# ATmega16A device description
Architecture: AVR8; Family: megaAVR
Registers are 8-bit, access not given, no defined reset value unless marked. A register's access mark holds for its fields unless they carry their own. Offsets are from the block's base; [hi:lo] are bit positions.

## TWI — Two Wire Serial Interface
Instances: TWI 0x00
0x20 TWBR — TWI Bit Rate register
  [7:0] TWBR — TWI Bit Rate bits
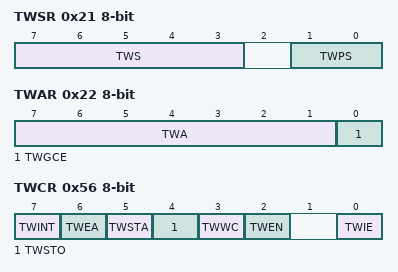
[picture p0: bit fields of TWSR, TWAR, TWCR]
0x21 TWSR — TWI Status Register
  [7:3] TWS (bit 3 of the value upward) — TWI Status
  [1:0] TWPS — TWI Prescaler
    0=1; 1=4; 2=16; 3=64
0x22 TWAR — TWI (Slave) Address register
  [7:1] TWA — TWI (Slave) Address register Bits
  [0] TWGCE — TWI General Call Recognition Enable Bit
0x23 TWDR — TWI Data register
  [7:0] TWD — TWI Data bits
0x56 TWCR — TWI Control Register
  [7] TWINT — TWI Interrupt Flag
  [6] TWEA — TWI Enable Acknowledge Bit
  [5] TWSTA — TWI Start Condition Bit
  [4] TWSTO — TWI Stop Condition Bit
  [3] TWWC — TWI Write Collition Flag
  [2] TWEN — TWI Enable Bit
  [0] TWIE — TWI Interrupt Enable

## AC — Analog Comparator
Instances: AC 0x00
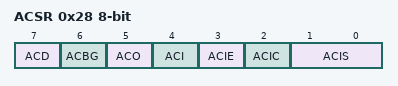
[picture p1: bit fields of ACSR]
0x28 ACSR — Analog Comparator Control And Status Register
  [7] ACD — Analog Comparator Disable
  [6] ACBG — Analog Comparator Bandgap Select
  [5] ACO — Analog Compare Output
  [4] ACI — Analog Comparator Interrupt Flag
  [3] ACIE — Analog Comparator Interrupt Enable
  [2] ACIC — Analog Comparator Input Capture Enable
  [1:0] ACIS — Analog Comparator Interrupt Mode Select bits
    0=Interrupt on Toggle; 2=Interrupt on Falling Edge; 3=Interrupt on Rising Edge
0x50 SFIOR — Special Function IO Register
  [3] ACME — Analog Comparator Multiplexer Enable

## ADC — Analog-to-Digital Converter
Instances: ADC 0x00
0x24 ADC 16-bit — ADC Data Register Bytes
  [9:0] ADC — ADC Data Bits
    0=2; 1=2; 2=4; 3=8; 4=16; 5=32; 6=64; 7=128
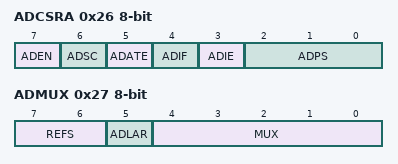
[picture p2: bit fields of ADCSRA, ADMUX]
0x26 ADCSRA — The ADC Control and Status register
  [7] ADEN — ADC Enable
  [6] ADSC — ADC Start Conversion
  [5] ADATE — ADC Auto Trigger
  [4] ADIF — ADC Interrupt Flag
  [3] ADIE — ADC Interrupt Enable
  [2:0] ADPS — ADC Prescaler Select Bits
    0=2; 1=2; 2=4; 3=8; 4=16; 5=32; 6=64; 7=128
0x27 ADMUX — The ADC multiplexer Selection Register
  [7:6] REFS — Reference Selection Bits
    0=AREF, Internal Vref turned off; 1=AVCC with external capacitor at AREF pin; 3=Internal 2.56V Voltage Reference with external capacitor at AREF pin
  [5] ADLAR — Left Adjust Result
  [4:0] MUX — Analog Channel and Gain Selection Bits
0x50 SFIOR — Special Function IO Register
  [7:5] ADTS — ADC Auto Trigger Sources

## JTAG — JTAG Interface
Instances: JTAG 0x00
0x51 OCDR — On-Chip Debug Related Register in I/O Memory
  [7:0] OCDR — On-Chip Debug Register Bits
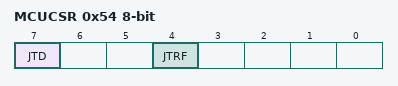
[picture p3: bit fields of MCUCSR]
0x54 MCUCSR — MCU Control And Status Register
  [7] JTD — JTAG Interface Disable
  [4] JTRF — JTAG Reset Flag

## BOOT_LOAD — Bootloader
Instances: BOOT_LOAD 0x00
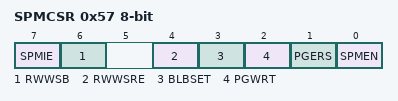
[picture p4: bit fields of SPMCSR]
0x57 SPMCSR — Store Program Memory Control Register
  [7] SPMIE — SPM Interrupt Enable
  [6] RWWSB — Read While Write Section Busy
  [4] RWWSRE — Read While Write section read enable
  [3] BLBSET — Boot Lock Bit Set
  [2] PGWRT — Page Write
  [1] PGERS — Page Erase
  [0] SPMEN — Store Program Memory Enable

## PORTA — I/O Port
Instances: PORTA 0x00
0x39 PINA — Port A Input Pins
0x3A DDRA — Port A Data Direction Register
0x3B PORTA — Port A Data Register

## PORTB — I/O Port
Instances: PORTB 0x00
0x36 PINB — Port B Input Pins
0x37 DDRB — Port B Data Direction Register
0x38 PORTB — Port B Data Register

## PORTC — I/O Port
Instances: PORTC 0x00
0x33 PINC — Port C Input Pins
0x34 DDRC — Port C Data Direction Register
0x35 PORTC — Port C Data Register

## PORTD — I/O Port
Instances: PORTD 0x00
0x30 PIND — Port D Input Pins
0x31 DDRD — Port D Data Direction Register
0x32 PORTD — Port D Data Register

## WDT — Watchdog Timer
Instances: WDT 0x00
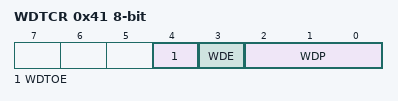
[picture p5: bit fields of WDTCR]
0x41 WDTCR — Watchdog Timer Control Register
  [4] WDTOE — RW
  [3] WDE — Watch Dog Enable
  [2:0] WDP — Watch Dog Timer Prescaler bits
    0=Oscillator Cycles 16K; 1=Oscillator Cycles 32K; 2=Oscillator Cycles 64K; 3=Oscillator Cycles 128K; 4=Oscillator Cycles 256K; 5=Oscillator Cycles 512K; 6=Oscillator Cycles 1024K; 7=Oscillator Cycles 2048K
